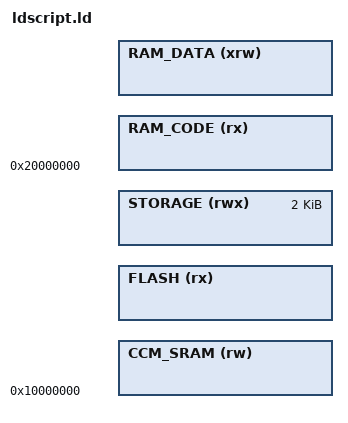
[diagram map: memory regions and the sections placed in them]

/* Linker script for STM32F3xx Devices */

/* Flash page size is 2k */
__FLASH_PAGE_SIZE = 0x800;

/* Specify the memory areas */
MEMORY
{
  RAM_CODE (rx)   : ORIGIN = 0x20000000, LENGTH = RAM_CODE_SIZE ? RAM_CODE_SIZE : 1K
  RAM_DATA (xrw)  : ORIGIN = 0x20000000 + LENGTH(RAM_CODE), LENGTH = RAM_SIZE - LENGTH(RAM_CODE)
  CCM_SRAM (rw)   : ORIGIN = 0x10000000, LENGTH = CCM_SRAM_SIZE ? CCM_SRAM_SIZE : 0K
  FLASH (rx)      : ORIGIN = 0x8000000 + FLASH_APP_OFFSET, LENGTH = FLASH_SIZE - FLASH_APP_OFFSET - __FLASH_PAGE_SIZE
  STORAGE(rwx)    : ORIGIN = 0x8000000 + LENGTH(FLASH), LENGTH = __FLASH_PAGE_SIZE
}

REGION_ALIAS("DMA_DATA", RAM_DATA)
REGION_ALIAS("FLASH_RAM_CODE", FLASH)
REGION_ALIAS("FLASH_STORAGE", STORAGE)

INCLUDE "variants/ldscript_gen.ld"
